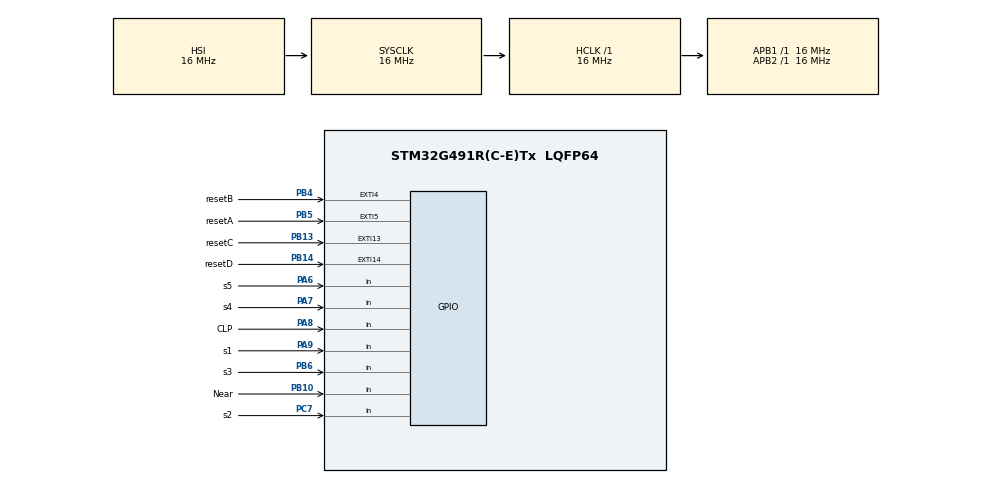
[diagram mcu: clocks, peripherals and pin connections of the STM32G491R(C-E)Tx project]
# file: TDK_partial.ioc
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Mcu.Family=STM32G4
Mcu.Name=STM32G491R(C-E)Tx
Mcu.Package=LQFP64
NVIC.EXTI15_10_IRQn=true\:0\:0\:false\:false\:true\:true\:true\:true
NVIC.EXTI4_IRQn=true\:0\:0\:false\:false\:true\:true\:true\:true
NVIC.EXTI9_5_IRQn=true\:0\:0\:false\:false\:true\:true\:true\:true
NVIC.PriorityGroup=NVIC_PRIORITYGROUP_4
NVIC.TIM6_DAC_IRQn=true\:0\:0\:false\:false\:true\:true\:true\:true
PA6.GPIO_Label=s5
PA6.Signal=GPIO_Input
PA7.GPIO_Label=s4
PA7.Signal=GPIO_Input
PA8.GPIO_Label=CLP
PA8.Signal=GPIO_Input
PA9.GPIO_Label=s1
PA9.Signal=GPIO_Input
PB10.GPIO_Label=Near
PB10.Signal=GPIO_Input
PB13.GPIO_Label=resetC
PB13.Signal=GPXTI13
PB14.GPIO_Label=resetD
PB14.Signal=GPXTI14
PB4.GPIO_Label=resetB
PB4.Signal=GPXTI4
PB5.GPIO_Label=resetA
PB5.Signal=GPXTI5
PB6.GPIO_Label=s3
PB6.Signal=GPIO_Input
PC7.GPIO_Label=s2
PC7.Signal=GPIO_Input
ProjectManager.HeapSize=0x200
ProjectManager.StackSize=0x400
ProjectManager.TargetToolchain=STM32CubeIDE
RCC.AHBFreq_Value=16000000
RCC.APB1Freq_Value=16000000
RCC.APB1TimFreq_Value=16000000
RCC.APB2Freq_Value=16000000
RCC.APB2TimFreq_Value=16000000
RCC.CortexFreq_Value=16000000
RCC.EXTERNAL_CLOCK_VALUE=12288000
RCC.HCLKFreq_Value=16000000
RCC.HSE_VALUE=8000000
RCC.HSI48_VALUE=48000000
RCC.HSI_VALUE=16000000
RCC.LSE_VALUE=32768
RCC.SYSCLKFreq_VALUE=16000000
RCC.USBFreq_Value=48000000
RCC.VCOOutputFreq_Value=128000000
TIM6.PeriodNoDither=10-1
TIM6.Prescaler=1600-1
VP_TIM6_VS_ClockSourceINT.Mode=Enable_Timer
board=custom

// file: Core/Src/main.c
/* USER CODE BEGIN Header */
/**
  ******************************************************************************
  * @file           : main.c
  * @brief          : Main program body
  ******************************************************************************
  * @attention
  *
  * Copyright (c) 2024 STMicroelectronics.
  * All rights reserved.
  *
  * This software is licensed under terms that can be found in the LICENSE file
  * in the root directory of this software component.
  * If no LICENSE file comes with this software, it is provided AS-IS.
  *
  ******************************************************************************
  */
/* USER CODE END Header */
#include "main.h"

/* USER CODE BEGIN Includes */
#include "mainpp.h"
/* USER CODE END Includes */

/* USER CODE BEGIN PD */
#define pi 3.14159265358979323846
/* USER CODE END PD */

TIM_HandleTypeDef htim6;

void SystemClock_Config(void);
static void MX_GPIO_Init(void);
static void MX_TIM6_Init(void);

int main(void)
{

  /* MCU Configuration--------------------------------------------------------*/

  /* Reset of all peripherals, Initializes the Flash interface and the Systick. */
  HAL_Init();

  /* Configure the system clock */
  SystemClock_Config();

  /* Initialize all configured peripherals */
  MX_GPIO_Init();
  MX_TIM6_Init();

  /* Infinite loop */
  while (1)
  {

  }
}

void SystemClock_Config(void)
{
  RCC_OscInitTypeDef RCC_OscInitStruct = {0};
  RCC_ClkInitTypeDef RCC_ClkInitStruct = {0};

  /** Configure the main internal regulator output voltage
  */
  HAL_PWREx_ControlVoltageScaling(PWR_REGULATOR_VOLTAGE_SCALE1);

  /** Initializes the RCC Oscillators according to the specified parameters
  * in the RCC_OscInitTypeDef structure.
  */
  RCC_OscInitStruct.OscillatorType = RCC_OSCILLATORTYPE_HSI;
  RCC_OscInitStruct.HSIState = RCC_HSI_ON;
  RCC_OscInitStruct.HSICalibrationValue = RCC_HSICALIBRATION_DEFAULT;
  RCC_OscInitStruct.PLL.PLLState = RCC_PLL_NONE;
  if (HAL_RCC_OscConfig(&RCC_OscInitStruct) != HAL_OK)
  {
    Error_Handler();
  }

  /** Initializes the CPU, AHB and APB buses clocks
  */
  RCC_ClkInitStruct.ClockType = RCC_CLOCKTYPE_HCLK|RCC_CLOCKTYPE_SYSCLK
                              |RCC_CLOCKTYPE_PCLK1|RCC_CLOCKTYPE_PCLK2;
  RCC_ClkInitStruct.SYSCLKSource = RCC_SYSCLKSOURCE_HSI;
  RCC_ClkInitStruct.AHBCLKDivider = RCC_SYSCLK_DIV1;
  RCC_ClkInitStruct.APB1CLKDivider = RCC_HCLK_DIV1;
  RCC_ClkInitStruct.APB2CLKDivider = RCC_HCLK_DIV1;

  if (HAL_RCC_ClockConfig(&RCC_ClkInitStruct, FLASH_LATENCY_0) != HAL_OK)
  {
    Error_Handler();
  }
}

static void MX_TIM6_Init(void)
{

  TIM_MasterConfigTypeDef sMasterConfig = {0};

  htim6.Instance = TIM6;
  htim6.Init.Prescaler = 1600-1;
  htim6.Init.CounterMode = TIM_COUNTERMODE_UP;
  htim6.Init.Period = 9;
  htim6.Init.AutoReloadPreload = TIM_AUTORELOAD_PRELOAD_DISABLE;
  if (HAL_TIM_Base_Init(&htim6) != HAL_OK)
  {
    Error_Handler();
  }
  sMasterConfig.MasterOutputTrigger = TIM_TRGO_RESET;
  sMasterConfig.MasterSlaveMode = TIM_MASTERSLAVEMODE_DISABLE;
  if (HAL_TIMEx_MasterConfigSynchronization(&htim6, &sMasterConfig) != HAL_OK)
  {
    Error_Handler();
  }

}

static void MX_GPIO_Init(void)
{
  GPIO_InitTypeDef GPIO_InitStruct = {0};

  /* GPIO Ports Clock Enable */
  __HAL_RCC_GPIOA_CLK_ENABLE();
  __HAL_RCC_GPIOB_CLK_ENABLE();
  __HAL_RCC_GPIOC_CLK_ENABLE();

  /*Configure GPIO pins : s5_Pin s4_Pin CLP_Pin s1_Pin */
  GPIO_InitStruct.Pin = s5_Pin|s4_Pin|CLP_Pin|s1_Pin;
  GPIO_InitStruct.Mode = GPIO_MODE_INPUT;
  GPIO_InitStruct.Pull = GPIO_NOPULL;
  HAL_GPIO_Init(GPIOA, &GPIO_InitStruct);

  /*Configure GPIO pins : Near_Pin s3_Pin */
  GPIO_InitStruct.Pin = Near_Pin|s3_Pin;
  GPIO_InitStruct.Mode = GPIO_MODE_INPUT;
  GPIO_InitStruct.Pull = GPIO_NOPULL;
  HAL_GPIO_Init(GPIOB, &GPIO_InitStruct);

  /*Configure GPIO pins : resetC_Pin resetD_Pin resetB_Pin resetA_Pin */
  GPIO_InitStruct.Pin = resetC_Pin|resetD_Pin|resetB_Pin|resetA_Pin;
  GPIO_InitStruct.Mode = GPIO_MODE_IT_RISING;
  GPIO_InitStruct.Pull = GPIO_NOPULL;
  HAL_GPIO_Init(GPIOB, &GPIO_InitStruct);

  /*Configure GPIO pin : s2_Pin */
  GPIO_InitStruct.Pin = s2_Pin;
  GPIO_InitStruct.Mode = GPIO_MODE_INPUT;
  GPIO_InitStruct.Pull = GPIO_NOPULL;
  HAL_GPIO_Init(s2_GPIO_Port, &GPIO_InitStruct);

  /* EXTI interrupt init*/
  HAL_NVIC_SetPriority(EXTI4_IRQn, 0, 0);
  HAL_NVIC_EnableIRQ(EXTI4_IRQn);

  HAL_NVIC_SetPriority(EXTI9_5_IRQn, 0, 0);
  HAL_NVIC_EnableIRQ(EXTI9_5_IRQn);

  HAL_NVIC_SetPriority(EXTI15_10_IRQn, 0, 0);
  HAL_NVIC_EnableIRQ(EXTI15_10_IRQn);

}

void Error_Handler(void)
{
  __disable_irq();
  while (1)
  {
  }
}
